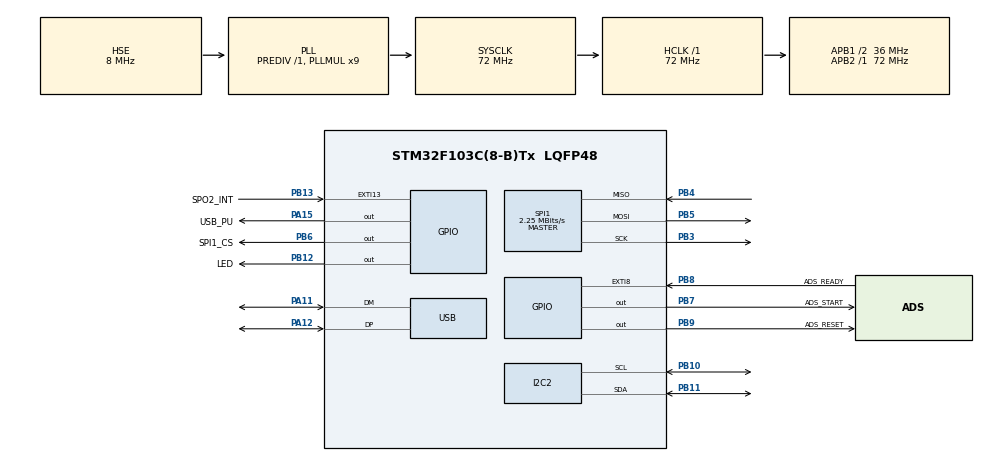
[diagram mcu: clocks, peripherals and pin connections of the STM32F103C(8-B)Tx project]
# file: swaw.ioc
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Dma.Request0=SPI1_TX
Dma.Request1=SPI1_RX
Dma.SPI1_RX.1.Direction=DMA_PERIPH_TO_MEMORY
Dma.SPI1_RX.1.Instance=DMA1_Channel2
Dma.SPI1_RX.1.MemDataAlignment=DMA_MDATAALIGN_BYTE
Dma.SPI1_RX.1.MemInc=DMA_MINC_ENABLE
Dma.SPI1_RX.1.Mode=DMA_NORMAL
Dma.SPI1_RX.1.PeriphDataAlignment=DMA_PDATAALIGN_BYTE
Dma.SPI1_RX.1.PeriphInc=DMA_PINC_DISABLE
Dma.SPI1_RX.1.Priority=DMA_PRIORITY_LOW
Dma.SPI1_TX.0.Direction=DMA_MEMORY_TO_PERIPH
Dma.SPI1_TX.0.Instance=DMA1_Channel3
Dma.SPI1_TX.0.MemDataAlignment=DMA_MDATAALIGN_BYTE
Dma.SPI1_TX.0.MemInc=DMA_MINC_ENABLE
Dma.SPI1_TX.0.Mode=DMA_NORMAL
Dma.SPI1_TX.0.PeriphDataAlignment=DMA_PDATAALIGN_BYTE
Dma.SPI1_TX.0.PeriphInc=DMA_PINC_DISABLE
Dma.SPI1_TX.0.Priority=DMA_PRIORITY_LOW
Mcu.Family=STM32F1
Mcu.Name=STM32F103C(8-B)Tx
Mcu.Package=LQFP48
NVIC.DMA1_Channel2_IRQn=true\:1\:0\:true\:false\:true\:false\:true\:true
NVIC.DMA1_Channel3_IRQn=true\:1\:0\:true\:false\:true\:false\:true\:true
NVIC.EXTI15_10_IRQn=true\:4\:0\:true\:false\:true\:true\:true\:true
NVIC.EXTI9_5_IRQn=true\:2\:0\:true\:false\:true\:true\:true\:true
NVIC.I2C2_ER_IRQn=true\:3\:0\:true\:false\:true\:true\:true\:true
NVIC.I2C2_EV_IRQn=true\:3\:0\:true\:false\:true\:true\:true\:true
NVIC.PriorityGroup=NVIC_PRIORITYGROUP_4
NVIC.USB_HP_CAN1_TX_IRQn=true\:0\:0\:false\:false\:true\:true\:true\:true
NVIC.USB_LP_CAN1_RX0_IRQn=true\:0\:0\:false\:false\:true\:false\:true\:true
PA11.Mode=Device
PA11.Signal=USB_DM
PA12.Mode=Device
PA12.Signal=USB_DP
PA13.Mode=Serial_Wire
PA13.Signal=SYS_JTMS-SWDIO
PA14.Mode=Serial_Wire
PA14.Signal=SYS_JTCK-SWCLK
PA15.GPIO_Label=USB_PU
PA15.Signal=GPIO_Output
PB10.Mode=I2C
PB10.Signal=I2C2_SCL
PB11.Mode=I2C
PB11.Signal=I2C2_SDA
PB12.GPIO_Label=LED
PB12.Signal=GPIO_Output
PB13.GPIO_Label=SPO2_INT
PB13.GPIO_ModeDefaultEXTI=GPIO_MODE_IT_FALLING
PB13.GPIO_PuPd=GPIO_PULLUP
PB13.Signal=GPXTI13
PB3.Mode=Full_Duplex_Master
PB3.Signal=SPI1_SCK
PB4.Mode=Full_Duplex_Master
PB4.Signal=SPI1_MISO
PB5.Mode=Full_Duplex_Master
PB5.Signal=SPI1_MOSI
PB6.GPIO_Label=SPI1_CS
PB6.GPIO_Speed=GPIO_SPEED_FREQ_MEDIUM
PB6.PinState=GPIO_PIN_SET
PB6.Signal=GPIO_Output
PB7.GPIO_Label=ADS_START
PB7.PinState=GPIO_PIN_RESET
PB7.Signal=GPIO_Output
PB8.GPIO_Label=ADS_READY
PB8.GPIO_ModeDefaultEXTI=GPIO_MODE_IT_FALLING
PB8.Signal=GPXTI8
PB9.GPIO_Label=ADS_RESET
PB9.PinState=GPIO_PIN_SET
PB9.Signal=GPIO_Output
PD0-OSC_IN.Mode=HSE-External-Oscillator
PD0-OSC_IN.Signal=RCC_OSC_IN
PD1-OSC_OUT.Mode=HSE-External-Oscillator
PD1-OSC_OUT.Signal=RCC_OSC_OUT
ProjectManager.HeapSize=0x200
ProjectManager.StackSize=0x400
ProjectManager.TargetToolchain=STM32CubeIDE
RCC.AHBFreq_Value=72000000
RCC.APB1CLKDivider=RCC_HCLK_DIV2
RCC.APB1Freq_Value=36000000
RCC.APB1TimFreq_Value=72000000
RCC.APB2Freq_Value=72000000
RCC.APB2TimFreq_Value=72000000
RCC.HCLKFreq_Value=72000000
RCC.PLLMUL=RCC_PLL_MUL9
RCC.SYSCLKFreq_VALUE=72000000
RCC.SYSCLKSource=RCC_SYSCLKSOURCE_PLLCLK
RCC.USBFreq_Value=48000000
RCC.USBPrescaler=RCC_USBCLKSOURCE_PLL_DIV1_5
SPI1.BaudRatePrescaler=SPI_BAUDRATEPRESCALER_32
SPI1.CLKPhase=SPI_PHASE_2EDGE
SPI1.CalculateBaudRate=2.25 MBits/s
SPI1.Direction=SPI_DIRECTION_2LINES
SPI1.Mode=SPI_MODE_MASTER
SPI1.VirtualType=VM_MASTER
USB_DEVICE.CLASS_NAME_FS=CDC
USB_DEVICE.CONFIGURATION_STRING_CDC_FS=Sleep monitor
USB_DEVICE.INTERFACE_STRING_CDC_FS=Sleep monitor
USB_DEVICE.MANUFACTURER_STRING=WZW TEAM
USB_DEVICE.PRODUCT_STRING_CDC_FS=Sleep monitor
USB_DEVICE.USBD_MAX_STR_DESC_SIZ=32
USB_DEVICE.USBD_SELF_POWERED=0
USB_DEVICE.VirtualMode=Cdc
USB_DEVICE.VirtualModeFS=Cdc_FS
VP_USB_DEVICE_VS_USB_DEVICE_CDC_FS.Mode=CDC_FS
board=custom

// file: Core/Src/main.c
/* USER CODE BEGIN Header */
/**
  ******************************************************************************
  * @file           : main.c
  * @brief          : Main program body
  ******************************************************************************
  * @attention
  *
  * Copyright (c) 2024 STMicroelectronics.
  * All rights reserved.
  *
  * This software is licensed under terms that can be found in the LICENSE file
  * in the root directory of this software component.
  * If no LICENSE file comes with this software, it is provided AS-IS.
  *
  ******************************************************************************
  */
/* USER CODE END Header */
#include "main.h"
#include "usb_device.h"

/* USER CODE BEGIN Includes */
#include "stm32f1xx.h"
#include "proto.h"
#include "scd40.h"
#include "ads.h"
#include "max30102.h"
/* USER CODE END Includes */

I2C_HandleTypeDef hi2c2;

SPI_HandleTypeDef hspi1;
DMA_HandleTypeDef hdma_spi1_tx;
DMA_HandleTypeDef hdma_spi1_rx;

void SystemClock_Config(void);
static void MX_GPIO_Init(void);
static void MX_DMA_Init(void);
static void MX_I2C2_Init(void);
static void MX_SPI1_Init(void);

int main(void)
{

  /* MCU Configuration--------------------------------------------------------*/

  /* Reset of all peripherals, Initializes the Flash interface and the Systick. */
  HAL_Init();

  /* Configure the system clock */
  SystemClock_Config();

  /* Initialize all configured peripherals */
  MX_GPIO_Init();
  MX_DMA_Init();
  MX_USB_DEVICE_Init();
  MX_I2C2_Init();
  MX_SPI1_Init();
  /* USER CODE BEGIN 2 */
  HAL_Delay(2000); //USB initialization apparently requires much time

  //enable USB pullup for USB enumeration
  HAL_GPIO_WritePin(USB_PU_GPIO_Port, USB_PU_Pin, GPIO_PIN_SET);

  Max30102Init(&hi2c2);
  Scd40Init(&hi2c2);
  AdsInit(&hspi1, &hdma_spi1_rx);

  /* USER CODE END 2 */

  /* Infinite loop */
  /* USER CODE BEGIN WHILE */
  while (1)
  {
	  Max30102Process();
	  ProtoProcess();
	  Scd40Process();
	  AdsProcess();
    /* USER CODE END WHILE */

  }
}

void SystemClock_Config(void)
{
  RCC_OscInitTypeDef RCC_OscInitStruct = {0};
  RCC_ClkInitTypeDef RCC_ClkInitStruct = {0};
  RCC_PeriphCLKInitTypeDef PeriphClkInit = {0};

  /** Initializes the RCC Oscillators according to the specified parameters
  * in the RCC_OscInitTypeDef structure.
  */
  RCC_OscInitStruct.OscillatorType = RCC_OSCILLATORTYPE_HSE;
  RCC_OscInitStruct.HSEState = RCC_HSE_ON;
  RCC_OscInitStruct.HSEPredivValue = RCC_HSE_PREDIV_DIV1;
  RCC_OscInitStruct.HSIState = RCC_HSI_ON;
  RCC_OscInitStruct.PLL.PLLState = RCC_PLL_ON;
  RCC_OscInitStruct.PLL.PLLSource = RCC_PLLSOURCE_HSE;
  RCC_OscInitStruct.PLL.PLLMUL = RCC_PLL_MUL9;
  if (HAL_RCC_OscConfig(&RCC_OscInitStruct) != HAL_OK)
  {
    Error_Handler();
  }

  /** Initializes the CPU, AHB and APB buses clocks
  */
  RCC_ClkInitStruct.ClockType = RCC_CLOCKTYPE_HCLK|RCC_CLOCKTYPE_SYSCLK
                              |RCC_CLOCKTYPE_PCLK1|RCC_CLOCKTYPE_PCLK2;
  RCC_ClkInitStruct.SYSCLKSource = RCC_SYSCLKSOURCE_PLLCLK;
  RCC_ClkInitStruct.AHBCLKDivider = RCC_SYSCLK_DIV1;
  RCC_ClkInitStruct.APB1CLKDivider = RCC_HCLK_DIV2;
  RCC_ClkInitStruct.APB2CLKDivider = RCC_HCLK_DIV1;

  if (HAL_RCC_ClockConfig(&RCC_ClkInitStruct, FLASH_LATENCY_2) != HAL_OK)
  {
    Error_Handler();
  }
  PeriphClkInit.PeriphClockSelection = RCC_PERIPHCLK_USB;
  PeriphClkInit.UsbClockSelection = RCC_USBCLKSOURCE_PLL_DIV1_5;
  if (HAL_RCCEx_PeriphCLKConfig(&PeriphClkInit) != HAL_OK)
  {
    Error_Handler();
  }
}

static void MX_I2C2_Init(void)
{

  hi2c2.Instance = I2C2;
  hi2c2.Init.ClockSpeed = 100000;
  hi2c2.Init.DutyCycle = I2C_DUTYCYCLE_2;
  hi2c2.Init.OwnAddress1 = 0;
  hi2c2.Init.AddressingMode = I2C_ADDRESSINGMODE_7BIT;
  hi2c2.Init.DualAddressMode = I2C_DUALADDRESS_DISABLE;
  hi2c2.Init.OwnAddress2 = 0;
  hi2c2.Init.GeneralCallMode = I2C_GENERALCALL_DISABLE;
  hi2c2.Init.NoStretchMode = I2C_NOSTRETCH_DISABLE;
  if (HAL_I2C_Init(&hi2c2) != HAL_OK)
  {
    Error_Handler();
  }

}

static void MX_SPI1_Init(void)
{

  /* SPI1 parameter configuration*/
  hspi1.Instance = SPI1;
  hspi1.Init.Mode = SPI_MODE_MASTER;
  hspi1.Init.Direction = SPI_DIRECTION_2LINES;
  hspi1.Init.DataSize = SPI_DATASIZE_8BIT;
  hspi1.Init.CLKPolarity = SPI_POLARITY_LOW;
  hspi1.Init.CLKPhase = SPI_PHASE_2EDGE;
  hspi1.Init.NSS = SPI_NSS_SOFT;
  hspi1.Init.BaudRatePrescaler = SPI_BAUDRATEPRESCALER_32;
  hspi1.Init.FirstBit = SPI_FIRSTBIT_MSB;
  hspi1.Init.TIMode = SPI_TIMODE_DISABLE;
  hspi1.Init.CRCCalculation = SPI_CRCCALCULATION_DISABLE;
  hspi1.Init.CRCPolynomial = 10;
  if (HAL_SPI_Init(&hspi1) != HAL_OK)
  {
    Error_Handler();
  }

}

static void MX_DMA_Init(void)
{

  /* DMA controller clock enable */
  __HAL_RCC_DMA1_CLK_ENABLE();

  /* DMA interrupt init */
  /* DMA1_Channel2_IRQn interrupt configuration */
  HAL_NVIC_SetPriority(DMA1_Channel2_IRQn, 1, 0);
  HAL_NVIC_EnableIRQ(DMA1_Channel2_IRQn);
  /* DMA1_Channel3_IRQn interrupt configuration */
  HAL_NVIC_SetPriority(DMA1_Channel3_IRQn, 1, 0);
  HAL_NVIC_EnableIRQ(DMA1_Channel3_IRQn);

}

static void MX_GPIO_Init(void)
{
  GPIO_InitTypeDef GPIO_InitStruct = {0};

  /* GPIO Ports Clock Enable */
  __HAL_RCC_GPIOD_CLK_ENABLE();
  __HAL_RCC_GPIOB_CLK_ENABLE();
  __HAL_RCC_GPIOA_CLK_ENABLE();

  /*Configure GPIO pin Output Level */
  HAL_GPIO_WritePin(GPIOB, LED_Pin|ADS_START_Pin, GPIO_PIN_RESET);

  /*Configure GPIO pin Output Level */
  HAL_GPIO_WritePin(USB_PU_GPIO_Port, USB_PU_Pin, GPIO_PIN_RESET);

  /*Configure GPIO pin Output Level */
  HAL_GPIO_WritePin(GPIOB, SPI1_CS_Pin|ADS_RESET_Pin, GPIO_PIN_SET);

  /*Configure GPIO pins : LED_Pin ADS_START_Pin ADS_RESET_Pin */
  GPIO_InitStruct.Pin = LED_Pin|ADS_START_Pin|ADS_RESET_Pin;
  GPIO_InitStruct.Mode = GPIO_MODE_OUTPUT_PP;
  GPIO_InitStruct.Pull = GPIO_NOPULL;
  GPIO_InitStruct.Speed = GPIO_SPEED_FREQ_LOW;
  HAL_GPIO_Init(GPIOB, &GPIO_InitStruct);

  /*Configure GPIO pin : SPO2_INT_Pin */
  GPIO_InitStruct.Pin = SPO2_INT_Pin;
  GPIO_InitStruct.Mode = GPIO_MODE_IT_FALLING;
  GPIO_InitStruct.Pull = GPIO_PULLUP;
  HAL_GPIO_Init(SPO2_INT_GPIO_Port, &GPIO_InitStruct);

  /*Configure GPIO pin : USB_PU_Pin */
  GPIO_InitStruct.Pin = USB_PU_Pin;
  GPIO_InitStruct.Mode = GPIO_MODE_OUTPUT_PP;
  GPIO_InitStruct.Pull = GPIO_NOPULL;
  GPIO_InitStruct.Speed = GPIO_SPEED_FREQ_LOW;
  HAL_GPIO_Init(USB_PU_GPIO_Port, &GPIO_InitStruct);

  /*Configure GPIO pin : SPI1_CS_Pin */
  GPIO_InitStruct.Pin = SPI1_CS_Pin;
  GPIO_InitStruct.Mode = GPIO_MODE_OUTPUT_PP;
  GPIO_InitStruct.Pull = GPIO_NOPULL;
  GPIO_InitStruct.Speed = GPIO_SPEED_FREQ_MEDIUM;
  HAL_GPIO_Init(SPI1_CS_GPIO_Port, &GPIO_InitStruct);

  /*Configure GPIO pin : ADS_READY_Pin */
  GPIO_InitStruct.Pin = ADS_READY_Pin;
  GPIO_InitStruct.Mode = GPIO_MODE_IT_FALLING;
  GPIO_InitStruct.Pull = GPIO_NOPULL;
  HAL_GPIO_Init(ADS_READY_GPIO_Port, &GPIO_InitStruct);

  /* EXTI interrupt init*/
  HAL_NVIC_SetPriority(EXTI9_5_IRQn, 2, 0);
  HAL_NVIC_EnableIRQ(EXTI9_5_IRQn);

  HAL_NVIC_SetPriority(EXTI15_10_IRQn, 4, 0);
  HAL_NVIC_EnableIRQ(EXTI15_10_IRQn);

}

void Error_Handler(void)
{
  __disable_irq();
  while (1)
  {
  }
}
